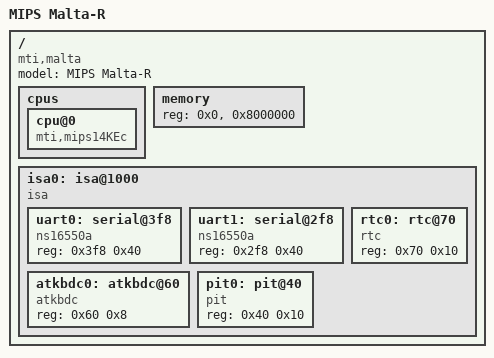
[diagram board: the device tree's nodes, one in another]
/dts-v1/;

/ {
    model = "MIPS Malta-R";
    compatible = "mti,malta";

	  cpus {
		    cpu@0 {
			      compatible = "mti,mips14KEc", "mti,mips14Kc";
		    };
	  };

    memory {
        device_type = "memory";
        reg = <0x0, 0x8000000>; // 256M
    };


    isa0: isa@1000 {
        compatible = "isa";
        #address-cells = <1>;
        #size-cells = <1>;

        uart0: serial@3f8 {
            compatible = "ns16550a";
            reg = <0x3f8 0x40>;
        };

        uart1: serial@2f8 {
            compatible = "ns16550a";
            reg = <0x2f8 0x40>;
        };

        rtc0: rtc@70 {
            compatible = "rtc";
            reg = <0x70 0x10>;
        };

        atkbdc0: atkbdc@60 {
            compatible = "atkbdc";
            reg = <0x60 0x8>;
        };

        pit0: pit@40 {
            compatible = "pit";
            reg = <0x40 0x10>;
        };

    };

};

